# ing920 register map
Vendor: INGChips; Series: ing920xx; File version: 1.0
CPU: CM3 r2p1, little endian, no MPU, no FPU, 2 interrupt priority bits
Registers are 32-bit, read-write, reset 0x0 unless marked. A register's access mark holds for its fields unless they carry their own. Offsets are from the block's base; [hi:lo] are bit positions; {n}, {i} and the like mark numbered series.

## io_mux_ctrl
Base 0x40006000
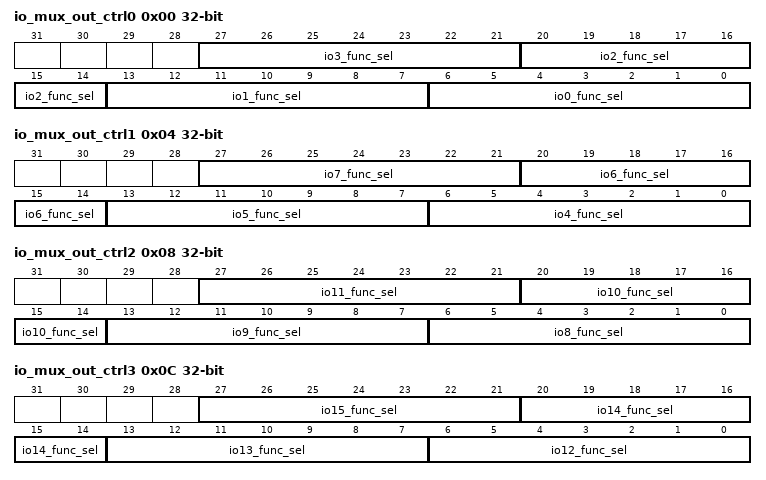
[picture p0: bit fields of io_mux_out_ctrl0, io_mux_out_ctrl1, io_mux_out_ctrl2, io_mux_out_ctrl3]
0x00 io_mux_out_ctrl0 — reg description:
  [7n+6:7n] io{n}_func_sel (n=0..3) — reg description:
0x04 io_mux_out_ctrl1 — reg description:
  [7n-22:7n-28] io{n}_func_sel (n=4..7) — reg description:
0x08 io_mux_out_ctrl2 — reg description:
  [7n-50:7n-56] io{n}_func_sel (n=8..11) — reg description:
0x0C io_mux_out_ctrl3 — reg description:
  [7n-78:7n-84] io{n}_func_sel (n=12..15) — reg description:
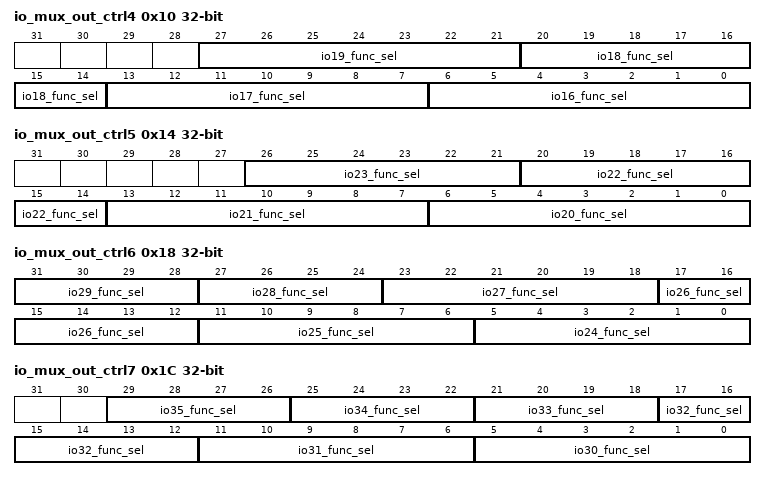
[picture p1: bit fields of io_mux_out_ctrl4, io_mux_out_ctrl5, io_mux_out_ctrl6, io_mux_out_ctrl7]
0x10 io_mux_out_ctrl4 — reg description:
  [7n-106:7n-112] io{n}_func_sel (n=16..19) — reg description:
0x14 io_mux_out_ctrl5 — reg description:
  [26:21] io23_func_sel — reg description:
  [20:14] io22_func_sel — reg description:
  [13:7] io21_func_sel — reg description:
  [6:0] io20_func_sel — reg description:
0x18 io_mux_out_ctrl6 — reg description:
  [31:28] io29_func_sel — reg description:
  [27:24] io28_func_sel — reg description:
  [6n-139:6n-144] io{n}_func_sel (n=24..27) — reg description:
0x1C io_mux_out_ctrl7 — reg description:
  [29:26] io35_func_sel — reg description:
  [25:22] io34_func_sel — reg description:
  [21:18] io33_func_sel — reg description:
  [17:12] io32_func_sel — reg description:
  [11:6] io31_func_sel — reg description:
  [5:0] io30_func_sel — reg description:
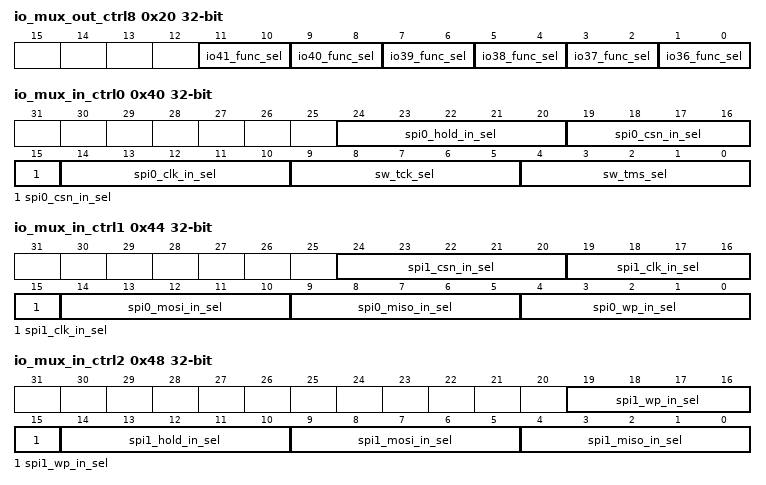
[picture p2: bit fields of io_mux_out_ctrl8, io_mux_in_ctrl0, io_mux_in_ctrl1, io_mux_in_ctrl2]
0x20 io_mux_out_ctrl8 — reg description:
  [2n-71:2n-72] io{n}_func_sel (n=36..41) — reg description:
0x40 io_mux_in_ctrl0 — reg description:
  [24:20] spi0_hold_in_sel — reg description:
  [19:15] spi0_csn_in_sel — reg description:
  [14:10] spi0_clk_in_sel — reg description:
  [9:5] sw_tck_sel — reg description:
  [4:0] sw_tms_sel — reg description:
0x44 io_mux_in_ctrl1 — reg description:
  [24:20] spi1_csn_in_sel — reg description:
  [19:15] spi1_clk_in_sel — reg description:
  [14:10] spi0_mosi_in_sel — reg description:
  [9:5] spi0_miso_in_sel — reg description:
  [4:0] spi0_wp_in_sel — reg description:
0x48 io_mux_in_ctrl2 — reg description:
  [19:15] spi1_wp_in_sel — reg description:
  [14:10] spi1_hold_in_sel — reg description:
  [9:5] spi1_mosi_in_sel — reg description:
  [4:0] spi1_miso_in_sel — reg description:
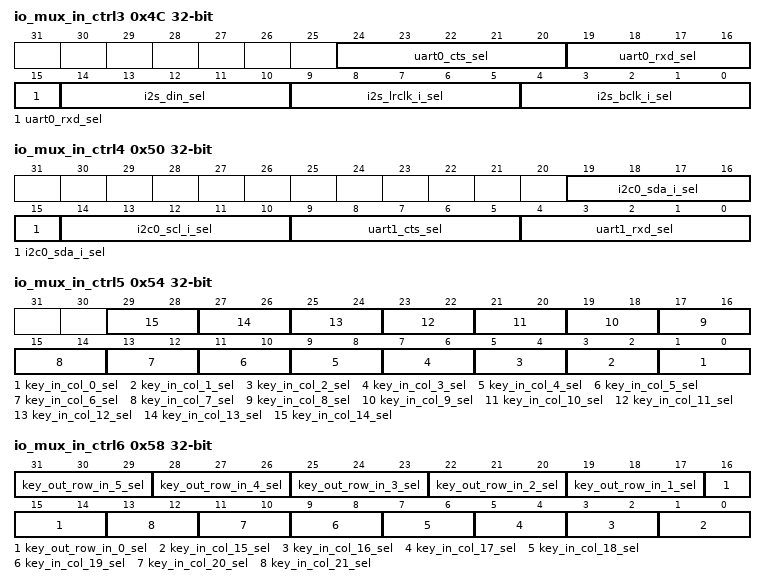
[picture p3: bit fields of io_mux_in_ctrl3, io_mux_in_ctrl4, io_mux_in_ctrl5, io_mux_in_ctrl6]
0x4C io_mux_in_ctrl3 — reg description:
  [24:20] uart0_cts_sel — reg description:
  [19:15] uart0_rxd_sel — reg description:
  [14:10] i2s_din_sel — reg description:
  [9:5] i2s_lrclk_i_sel — reg description:
  [4:0] i2s_bclk_i_sel — reg description:
0x50 io_mux_in_ctrl4 — reg description:
  [19:15] i2c0_sda_i_sel — reg description:
  [14:10] i2c0_scl_i_sel — reg description:
  [9:5] uart1_cts_sel — reg description:
  [4:0] uart1_rxd_sel — reg description:
0x54 io_mux_in_ctrl5 — reg description:
  [2n+1:2n] key_in_col_{n}_sel (n=0..14) — reg description:
0x58 io_mux_in_ctrl6 — reg description:
  [3n+16:3n+14] key_out_row_in_{n}_sel (n=0..5) — reg description:
  [2n-29:2n-30] key_in_col_{n}_sel (n=15..21) — reg description:
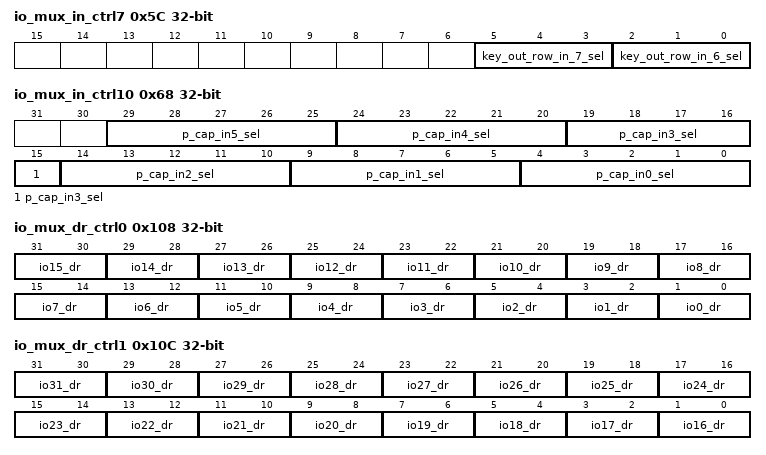
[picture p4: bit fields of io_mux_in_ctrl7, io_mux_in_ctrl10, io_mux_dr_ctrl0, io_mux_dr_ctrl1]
0x5C io_mux_in_ctrl7 — reg description:
  [5:3] key_out_row_in_7_sel — reg description:
  [2:0] key_out_row_in_6_sel — reg description:
0x64 io_mux_in_ctrl9 — reg description:
0x68 io_mux_in_ctrl10 — reg description:
  [5n+4:5n] p_cap_in{n}_sel (n=0..5) — reg description:
0x6C io_mux_in_ctrl11 — reg description:
  [4:0] dimc_dat_sel
0x80 io_pe_ctrl0 — reg description:
  [31:0] io_pe_lsb
0x84 io_pe_ctrl1 — reg description:
  [9:0] io_pe_msb
0x88 io_ps_ctrl0 — reg description:
  [31:0] io_ps_lsb
0x8C io_ps_ctrl1 — reg description:
  [9:0] io_ps_msb
0x90 io_pu_sel_ctrl0 — reg description:
  [31:0] io_pu_sel_lsb
0x94 io_pu_sel_ctrl1 — reg description:
  [9:0] io_pu_sel_msb
0x100 io_mux_is_ctrl0 — reg description:
  [31:0] io_is_lsb
0x104 io_mux_is_ctrl1 — reg description:
  [9:0] io_is_msb
0x108 io_mux_dr_ctrl0 — reg description:
  [2n+1:2n] io{n}_dr (n=0..15) — reg description:
0x10C io_mux_dr_ctrl1 — reg description:
  [2n-31:2n-32] io{n}_dr (n=16..31) — reg description:
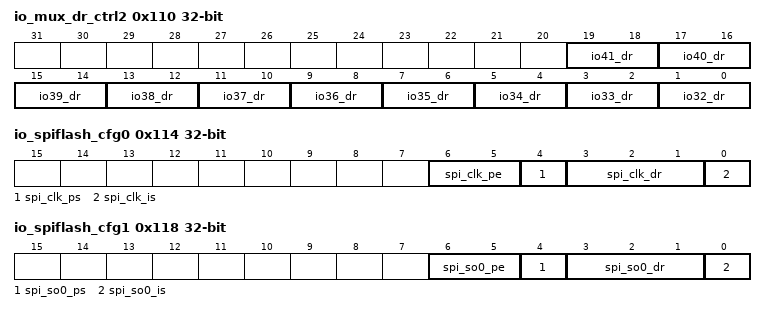
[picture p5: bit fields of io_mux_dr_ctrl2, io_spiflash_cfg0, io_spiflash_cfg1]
0x110 io_mux_dr_ctrl2 — reg description:
  [2n-63:2n-64] io{n}_dr (n=32..41) — reg description:
0x114 io_spiflash_cfg0 — reg description:
  [6:5] spi_clk_pe — reg description:
  [4] spi_clk_ps — reg description:
  [3:1] spi_clk_dr — reg description:
  [0] spi_clk_is — reg description:
0x118 io_spiflash_cfg1 — reg description:
  [6:5] spi_so0_pe — reg description:
  [4] spi_so0_ps — reg description:
  [3:1] spi_so0_dr — reg description:
  [0] spi_so0_is — reg description:
